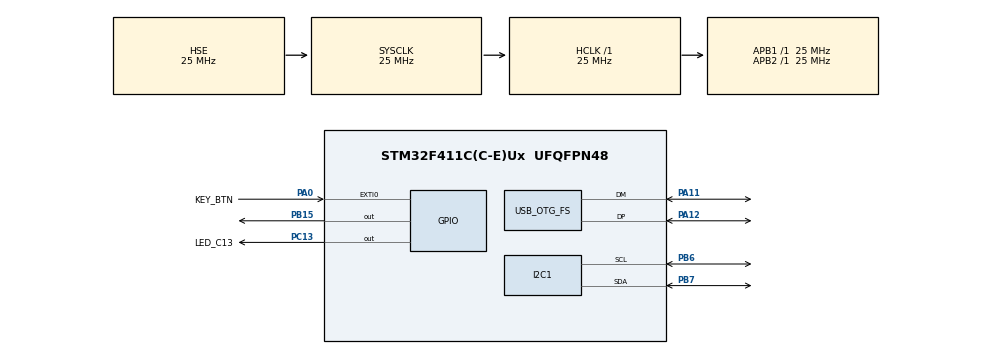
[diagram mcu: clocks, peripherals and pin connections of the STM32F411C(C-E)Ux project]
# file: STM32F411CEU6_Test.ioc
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Mcu.Family=STM32F4
Mcu.Name=STM32F411C(C-E)Ux
Mcu.Package=UFQFPN48
NVIC.EXTI0_IRQn=true\:0\:0\:false\:false\:true\:true\:true
NVIC.OTG_FS_IRQn=true\:0\:0\:false\:false\:true\:false\:true
NVIC.PriorityGroup=NVIC_PRIORITYGROUP_4
PA0-WKUP.GPIO_Label=KEY_BTN
PA0-WKUP.GPIO_ModeDefaultEXTI=GPIO_MODE_IT_FALLING
PA0-WKUP.GPIO_PuPd=GPIO_PULLUP
PA0-WKUP.Signal=GPXTI0
PA11.Mode=Device_Only
PA11.Signal=USB_OTG_FS_DM
PA12.Mode=Device_Only
PA12.Signal=USB_OTG_FS_DP
PA13.Mode=Serial_Wire
PA13.Signal=SYS_JTMS-SWDIO
PA14.Mode=Serial_Wire
PA14.Signal=SYS_JTCK-SWCLK
PB15.Signal=GPIO_Output
PB6.Mode=I2C
PB6.Signal=I2C1_SCL
PB7.Mode=I2C
PB7.Signal=I2C1_SDA
PC13-ANTI_TAMP.GPIO_Label=LED_C13
PC13-ANTI_TAMP.Signal=GPIO_Output
PC14-OSC32_IN.Mode=LSE-External-Oscillator
PC14-OSC32_IN.Signal=RCC_OSC32_IN
PC15-OSC32_OUT.Mode=LSE-External-Oscillator
PC15-OSC32_OUT.Signal=RCC_OSC32_OUT
PH0\ -\ OSC_IN.Mode=HSE-External-Oscillator
PH0\ -\ OSC_IN.Signal=RCC_OSC_IN
PH1\ -\ OSC_OUT.Mode=HSE-External-Oscillator
PH1\ -\ OSC_OUT.Signal=RCC_OSC_OUT
ProjectManager.HeapSize=0x200
ProjectManager.StackSize=0x400
ProjectManager.TargetToolchain=STM32CubeIDE
RCC.48MHZClocksFreq_Value=48000000
RCC.AHBFreq_Value=25000000
RCC.APB1Freq_Value=25000000
RCC.APB1TimFreq_Value=25000000
RCC.APB2Freq_Value=25000000
RCC.APB2TimFreq_Value=25000000
RCC.CortexFreq_Value=25000000
RCC.HCLKFreq_Value=25000000
RCC.HSE_VALUE=25000000
RCC.HSI_VALUE=16000000
RCC.PLLM=15
RCC.PLLN=144
RCC.PLLQ=5
RCC.SYSCLKFreq_VALUE=25000000
RCC.SYSCLKSource=RCC_SYSCLKSOURCE_HSE
RCC.VCOOutputFreq_Value=240000000
USB_DEVICE.CLASS_NAME_FS=CDC
USB_DEVICE.VirtualMode=Cdc
USB_DEVICE.VirtualModeFS=Cdc_FS
USB_OTG_FS.VirtualMode=Device_Only
VP_USB_DEVICE_VS_USB_DEVICE_CDC_FS.Mode=CDC_FS
board=custom

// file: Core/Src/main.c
/* USER CODE BEGIN Header */
/**
  ******************************************************************************
  * @file           : main.c
  * @brief          : Main program body
  ******************************************************************************
  * @attention
  *
  * <h2><center>&copy; Copyright (c) 2021 STMicroelectronics.
  * All rights reserved.</center></h2>
  *
  * This software component is licensed by ST under BSD 3-Clause license,
  * the "License"; You may not use this file except in compliance with the
  * License. You may obtain a copy of the License at:
  *                        opensource.org/licenses/BSD-3-Clause
  *
  ******************************************************************************
  */
/* USER CODE END Header */
#include "main.h"
#include "usb_device.h"

/* USER CODE BEGIN Includes */
#include "usbd_cdc_if.h"
#include "AHT20.h"
#include <math.h>
/* USER CODE END Includes */

I2C_HandleTypeDef hi2c1;

/* USER CODE BEGIN PV */
AHT20 thSensor; //Sensor struct
/* USER CODE END PV */

void SystemClock_Config(void);
static void MX_GPIO_Init(void);
static void MX_I2C1_Init(void);
/* USER CODE BEGIN PFP */
void HAL_GPIO_EXTI_Callback(uint16_t GPIO_Pin);
/* USER CODE END PFP */

int main(void)
{

  /* MCU Configuration--------------------------------------------------------*/

  /* Reset of all peripherals, Initializes the Flash interface and the Systick. */
  HAL_Init();

  /* Configure the system clock */
  SystemClock_Config();

  /* Initialize all configured peripherals */
  MX_GPIO_Init();
  MX_I2C1_Init();
  MX_USB_DEVICE_Init();
  /* USER CODE BEGIN 2 */

  /* Initialize the AHT20 Sensor */
  AHT20_Init( &thSensor, &hi2c1 );
  char logBuf[32];

  /* USER CODE END 2 */

  /* Infinite loop */
  while (1)
  {

    /* USER CODE BEGIN 3 */

	  /* Read & Calculate Sensor Values */
	  AHT20_ReadTempHum_Data( &thSensor );

	  sprintf(logBuf, "%.2f degC\t %.2f %\r\n", thSensor.tempC, thSensor.humPercent);

	  CDC_Transmit_FS((uint8_t *) logBuf, strlen(logBuf));

	  HAL_Delay(1000);

  }
  /* USER CODE END 3 */
}

void SystemClock_Config(void)
{
  RCC_OscInitTypeDef RCC_OscInitStruct = {0};
  RCC_ClkInitTypeDef RCC_ClkInitStruct = {0};

  /** Configure the main internal regulator output voltage
  */
  __HAL_RCC_PWR_CLK_ENABLE();
  __HAL_PWR_VOLTAGESCALING_CONFIG(PWR_REGULATOR_VOLTAGE_SCALE1);
  /** Initializes the RCC Oscillators according to the specified parameters
  * in the RCC_OscInitTypeDef structure.
  */
  RCC_OscInitStruct.OscillatorType = RCC_OSCILLATORTYPE_HSE;
  RCC_OscInitStruct.HSEState = RCC_HSE_ON;
  RCC_OscInitStruct.PLL.PLLState = RCC_PLL_ON;
  RCC_OscInitStruct.PLL.PLLSource = RCC_PLLSOURCE_HSE;
  RCC_OscInitStruct.PLL.PLLM = 15;
  RCC_OscInitStruct.PLL.PLLN = 144;
  RCC_OscInitStruct.PLL.PLLP = RCC_PLLP_DIV2;
  RCC_OscInitStruct.PLL.PLLQ = 5;
  if (HAL_RCC_OscConfig(&RCC_OscInitStruct) != HAL_OK)
  {
    Error_Handler();
  }
  /** Initializes the CPU, AHB and APB buses clocks
  */
  RCC_ClkInitStruct.ClockType = RCC_CLOCKTYPE_HCLK|RCC_CLOCKTYPE_SYSCLK
                              |RCC_CLOCKTYPE_PCLK1|RCC_CLOCKTYPE_PCLK2;
  RCC_ClkInitStruct.SYSCLKSource = RCC_SYSCLKSOURCE_HSE;
  RCC_ClkInitStruct.AHBCLKDivider = RCC_SYSCLK_DIV1;
  RCC_ClkInitStruct.APB1CLKDivider = RCC_HCLK_DIV1;
  RCC_ClkInitStruct.APB2CLKDivider = RCC_HCLK_DIV1;

  if (HAL_RCC_ClockConfig(&RCC_ClkInitStruct, FLASH_LATENCY_0) != HAL_OK)
  {
    Error_Handler();
  }
}

static void MX_I2C1_Init(void)
{

  hi2c1.Instance = I2C1;
  hi2c1.Init.ClockSpeed = 100000;
  hi2c1.Init.DutyCycle = I2C_DUTYCYCLE_2;
  hi2c1.Init.OwnAddress1 = 0;
  hi2c1.Init.AddressingMode = I2C_ADDRESSINGMODE_7BIT;
  hi2c1.Init.DualAddressMode = I2C_DUALADDRESS_DISABLE;
  hi2c1.Init.OwnAddress2 = 0;
  hi2c1.Init.GeneralCallMode = I2C_GENERALCALL_DISABLE;
  hi2c1.Init.NoStretchMode = I2C_NOSTRETCH_DISABLE;
  if (HAL_I2C_Init(&hi2c1) != HAL_OK)
  {
    Error_Handler();
  }

}

static void MX_GPIO_Init(void)
{
  GPIO_InitTypeDef GPIO_InitStruct = {0};

  /* GPIO Ports Clock Enable */
  __HAL_RCC_GPIOC_CLK_ENABLE();
  __HAL_RCC_GPIOH_CLK_ENABLE();
  __HAL_RCC_GPIOA_CLK_ENABLE();
  __HAL_RCC_GPIOB_CLK_ENABLE();

  /*Configure GPIO pin Output Level */
  HAL_GPIO_WritePin(LED_C13_GPIO_Port, LED_C13_Pin, GPIO_PIN_RESET);

  /*Configure GPIO pin Output Level */
  HAL_GPIO_WritePin(GPIOB, GPIO_PIN_15, GPIO_PIN_RESET);

  /*Configure GPIO pin : LED_C13_Pin */
  GPIO_InitStruct.Pin = LED_C13_Pin;
  GPIO_InitStruct.Mode = GPIO_MODE_OUTPUT_PP;
  GPIO_InitStruct.Pull = GPIO_NOPULL;
  GPIO_InitStruct.Speed = GPIO_SPEED_FREQ_LOW;
  HAL_GPIO_Init(LED_C13_GPIO_Port, &GPIO_InitStruct);

  /*Configure GPIO pin : KEY_BTN_Pin */
  GPIO_InitStruct.Pin = KEY_BTN_Pin;
  GPIO_InitStruct.Mode = GPIO_MODE_IT_FALLING;
  GPIO_InitStruct.Pull = GPIO_PULLUP;
  HAL_GPIO_Init(KEY_BTN_GPIO_Port, &GPIO_InitStruct);

  /*Configure GPIO pin : PB15 */
  GPIO_InitStruct.Pin = GPIO_PIN_15;
  GPIO_InitStruct.Mode = GPIO_MODE_OUTPUT_PP;
  GPIO_InitStruct.Pull = GPIO_NOPULL;
  GPIO_InitStruct.Speed = GPIO_SPEED_FREQ_LOW;
  HAL_GPIO_Init(GPIOB, &GPIO_InitStruct);

  /* EXTI interrupt init*/
  HAL_NVIC_SetPriority(EXTI0_IRQn, 0, 0);
  HAL_NVIC_EnableIRQ(EXTI0_IRQn);

}

/* USER CODE BEGIN 4 */
void HAL_GPIO_EXTI_Callback(uint16_t GPIO_Pin) {
	HAL_GPIO_TogglePin(LED_C13_GPIO_Port, LED_C13_Pin);
}
/* USER CODE END 4 */

void Error_Handler(void)
{
  __disable_irq();
  while (1)
  {
  }
}

/************************ (C) COPYRIGHT STMicroelectronics *****END OF FILE****/
